VERSION ""

NS_ :

BS_:

BU_: XXX LKAS ADRV SCC

CM_ "Kia EV4 CAN-FD DBC - Based on current confirmed & partially confirmed signals";
CM_ "Base: Hyundai/Kia CAN-FD platform (E-GMP / EV4)";
CM_ "Vehicle: Kia EV4 2024+";
CM_ "Status: WIP - Steering FD frame (0x395) updated based on drive4 steering-only logs";

BO_ 256 VEHICLE_STATE: 24 XXX
 SG_ COUNTER                     : 0|8@1+  (1,0) [0|255] "" XXX
 SG_ CHECKSUM                    : 8|8@1+  (1,0) [0|255] "" XXX
 SG_ COUNTER2                    : 16|8@1+ (1,0) [0|255] "" XXX
 SG_ GEAR_SHIFTER                : 32|4@1+ (1,0) [0|15] "" XXX
 SG_ DOOR_FL                     : 72|1@1+ (1,0) [0|1] "" XXX
 SG_ DOOR_FR                     : 73|1@1+ (1,0) [0|1] "" XXX
 SG_ DOOR_RL                     : 74|1@1+ (1,0) [0|1] "" XXX
 SG_ DOOR_RR                     : 75|1@1+ (1,0) [0|1] "" XXX
 SG_ SEATBELT_DRIVER_LATCHED     : 76|1@1+ (1,0) [0|1] "" XXX
 SG_ PARKING_BRAKE               : 119|1@1+ (1,0) [0|1] "" XXX

BO_ 272 POWERTRAIN: 32 XXX
 SG_ COUNTER                     : 0|8@1+  (1,0) [0|255] "" XXX
 SG_ CHECKSUM                    : 8|8@1+  (1,0) [0|255] "" XXX
 SG_ COUNTER2                    : 16|8@1+ (1,0) [0|255] "" XXX
 SG_ LEFT_BLINKER                : 168|1@1+ (1,0) [0|1] "" XXX
 SG_ RIGHT_BLINKER               : 169|1@1+ (1,0) [0|1] "" XXX
 SG_ REGEN_LEVEL                 : 176|4@1+ (1,0) [0|3] "" XXX

BO_ 357 BRAKE_ACCEL: 16 XXX
 SG_ COUNTER                     : 0|8@1+  (1,0) [0|255] "" XXX
 SG_ CHECKSUM                    : 8|8@1+  (1,0) [0|255] "" XXX
 SG_ COUNTER2                    : 16|8@1+ (1,0) [0|255] "" XXX
 SG_ BRAKE_PRESSURE              : 24|8@1+ (1,0) [0|255] "" XXX
 SG_ GAS_PEDAL                   : 40|8@1+ (1,0) [0|255] "" XXX

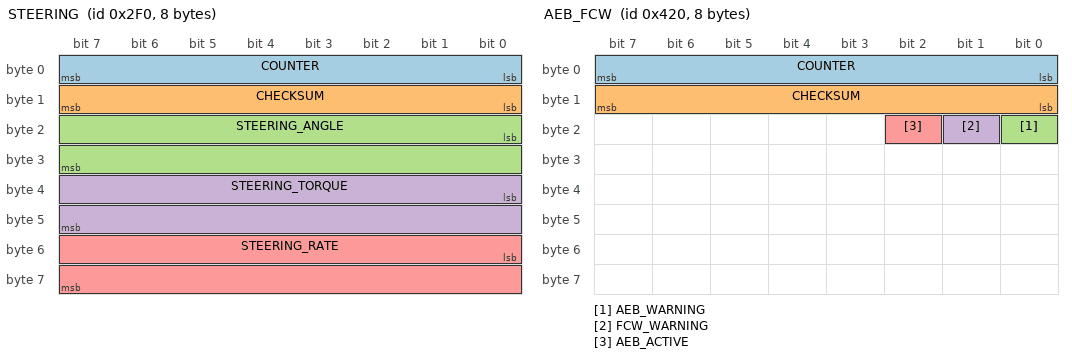
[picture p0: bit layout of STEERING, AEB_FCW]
BO_ 752 STEERING: 8 XXX
 SG_ COUNTER                     : 0|8@1+   (1,0) [0|255] "" XXX
 SG_ CHECKSUM                    : 8|8@1+   (1,0) [0|255] "" XXX
 SG_ STEERING_ANGLE              : 16|16@1- (0.1,0) [-450|450] "deg" XXX
 SG_ STEERING_TORQUE             : 32|16@1- (0.1,0) [-50|50] "Nm" XXX
 SG_ STEERING_RATE               : 48|16@1- (0.1,0) [-500|500] "deg/s" XXX

BO_ 864 WHEEL_SPEEDS_FL_RL: 32 XXX
 SG_ COUNTER                     : 0|8@1+  (1,0) [0|255] "" XXX
 SG_ CHECKSUM                    : 8|8@1+  (1,0) [0|255] "" XXX
 SG_ COUNTER2                    : 16|8@1+ (1,0) [0|255] "" XXX
 SG_ WHEEL_SPEED_FL              : 0|16@1+ (0.03125,0) [0|250] "kph" XXX
 SG_ WHEEL_SPEED_RL              : 16|16@1+ (0.03125,0) [0|250] "kph" XXX

BO_ 865 WHEEL_SPEEDS_FR_RR: 32 XXX
 SG_ COUNTER                     : 0|8@1+  (1,0) [0|255] "" XXX
 SG_ CHECKSUM                    : 8|8@1+  (1,0) [0|255] "" XXX
 SG_ COUNTER2                    : 16|8@1+ (1,0) [0|255] "" XXX
 SG_ WHEEL_SPEED_FR              : 0|16@1+ (0.03125,0) [0|250] "kph" XXX
 SG_ WHEEL_SPEED_RR              : 16|16@1+ (0.03125,0) [0|250] "kph" XXX

BO_ 896 TCS_ESC: 24 XXX
 SG_ COUNTER                     : 0|8@1+  (1,0) [0|255] "" XXX
 SG_ CHECKSUM                    : 8|8@1+  (1,0) [0|255] "" XXX
 SG_ COUNTER2                    : 16|8@1+ (1,0) [0|255] "" XXX
 SG_ ESP_DISABLED                : 24|1@1+ (1,0) [0|1] "" XXX
 SG_ ESP_ACTIVE                  : 25|1@1+ (1,0) [0|1] "" XXX
 SG_ TRACTION_CONTROL            : 26|1@1+ (1,0) [0|1] "" XXX
 SG_ ABS_ACTIVE                  : 27|1@1+ (1,0) [0|1] "" XXX

BO_ 917 STEERING_FD: 32 XXX
 SG_ STEER_FD_RAW_BYTE0         : 0|8@1+  (1,0) [0|255] "" XXX
 SG_ STEER_FD_RAW_BYTE1         : 8|8@1+  (1,0) [0|255] "" XXX
 SG_ STEER_FD_RAW_BYTE2         : 16|8@1+ (1,0) [0|255] "" XXX
 SG_ STEER_FD_STATUS_BYTE9      : 72|8@1+ (1,0) [0|255] "" XXX
 SG_ STEER_FD_STATUS_BYTE10     : 80|8@1+ (1,0) [0|255] "" XXX
 SG_ STEER_FD_STATUS_BYTE11     : 88|8@1+ (1,0) [0|255] "" XXX

BO_ 933 SCC_CONTROL: 24 XXX
 SG_ COUNTER                     : 0|8@1+  (1,0) [0|255] "" XXX
 SG_ CHECKSUM                    : 8|8@1+  (1,0) [0|255] "" XXX
 SG_ COUNTER2                    : 16|8@1+ (1,0) [0|255] "" XXX
 SG_ CRUISE_ACTIVE               : 24|1@1+ (1,0) [0|1] "" XXX
 SG_ CRUISE_STANDSTILL           : 25|1@1+ (1,0) [0|1] "" XXX
 SG_ CRUISE_AVAILABLE            : 26|1@1+ (1,0) [0|1] "" XXX
 SG_ SET_SPEED                   : 32|8@1+ (1,0) [0|255] "kph" XXX
 SG_ LEAD_DISTANCE               : 40|8@1+ (1,0) [0|255] "m" XXX
 SG_ LEAD_SPEED                  : 48|16@1- (0.1,0) [-200|200] "kph" XXX

BO_ 934 LKAS_1: 24 XXX
 SG_ COUNTER                     : 0|8@1+  (1,0) [0|255] "" XXX
 SG_ CHECKSUM                    : 8|8@1+  (1,0) [0|255] "" XXX
 SG_ COUNTER2                    : 16|8@1+ (1,0) [0|255] "" XXX
 SG_ LFA_ACTIVE                  : 24|1@1+ (1,0) [0|1] "" XXX
 SG_ LFA_AVAILABLE               : 25|1@1+ (1,0) [0|1] "" XXX
 SG_ LANE_DISTANCE_LEFT          : 32|8@1+ (0.01,0) [0|2.55] "m" XXX
 SG_ LANE_DISTANCE_RIGHT         : 40|8@1+ (0.01,0) [0|2.55] "m" XXX

BO_ 935 LKAS_2: 24 XXX
 SG_ COUNTER                     : 0|8@1+  (1,0) [0|255] "" XXX
 SG_ CHECKSUM                    : 8|8@1+  (1,0) [0|255] "" XXX
 SG_ COUNTER2                    : 16|8@1+ (1,0) [0|255] "" XXX
 SG_ LANE_DETECTED               : 24|1@1+ (1,0) [0|1] "" XXX
 SG_ LEFT_LANE_DETECTED          : 25|1@1+ (1,0) [0|1] "" XXX
 SG_ RIGHT_LANE_DETECTED         : 26|1@1+ (1,0) [0|1] "" XXX

BO_ 976 ADAS_1: 32 XXX
 SG_ COUNTER                     : 0|8@1+  (1,0) [0|255] "" XXX
 SG_ CHECKSUM                    : 8|8@1+  (1,0) [0|255] "" XXX
 SG_ COUNTER2                    : 16|8@1+ (1,0) [0|255] "" XXX
 SG_ ADAS_ENABLED                : 24|1@1+ (1,0) [0|1] "" XXX

BO_ 977 ADAS_2: 32 XXX
 SG_ COUNTER                     : 0|8@1+  (1,0) [0|255] "" XXX
 SG_ CHECKSUM                    : 8|8@1+  (1,0) [0|255] "" XXX
 SG_ COUNTER2                    : 16|8@1+ (1,0) [0|255] "" XXX

BO_ 1056 AEB_FCW: 8 XXX
 SG_ COUNTER                     : 0|8@1+  (1,0) [0|255] "" XXX
 SG_ CHECKSUM                    : 8|8@1+  (1,0) [0|255] "" XXX
 SG_ AEB_WARNING                 : 16|1@1+ (1,0) [0|1] "" XXX
 SG_ FCW_WARNING                 : 17|1@1+ (1,0) [0|1] "" XXX
 SG_ AEB_ACTIVE                  : 18|1@1+ (1,0) [0|1] "" XXX

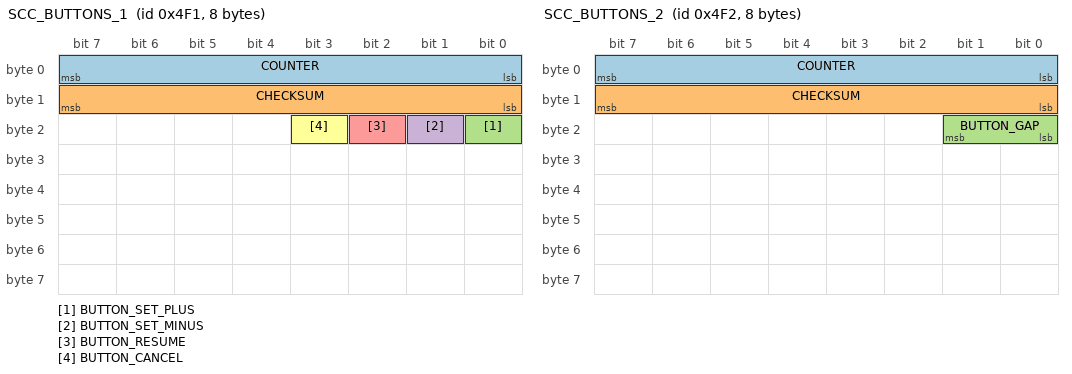
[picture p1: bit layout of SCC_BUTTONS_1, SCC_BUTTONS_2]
BO_ 1265 SCC_BUTTONS_1: 8 XXX
 SG_ COUNTER                     : 0|8@1+  (1,0) [0|255] "" XXX
 SG_ CHECKSUM                    : 8|8@1+  (1,0) [0|255] "" XXX
 SG_ BUTTON_SET_PLUS             : 16|1@1+ (1,0) [0|1] "" XXX
 SG_ BUTTON_SET_MINUS            : 17|1@1+ (1,0) [0|1] "" XXX
 SG_ BUTTON_RESUME               : 18|1@1+ (1,0) [0|1] "" XXX
 SG_ BUTTON_CANCEL               : 19|1@1+ (1,0) [0|1] "" XXX

BO_ 1266 SCC_BUTTONS_2: 8 XXX
 SG_ COUNTER                     : 0|8@1+  (1,0) [0|255] "" XXX
 SG_ CHECKSUM                    : 8|8@1+  (1,0) [0|255] "" XXX
 SG_ BUTTON_GAP                  : 16|2@1+ (1,0) [0|3] "" XXX

CM_ BO_ 256 "Vehicle state including gear, doors, seatbelt - Confirmed: Gear P/R/N/D";
CM_ BO_ 272 "Powertrain state including turn signals - Status: Turn signals unconfirmed";
CM_ BO_ 357 "Brake and accelerator pedal positions - Status: Gas pedal unconfirmed";
CM_ BO_ 752 "Steering wheel angle and torque (classic CAN) - PARTIAL: Needs validation vs CAN-FD";
CM_ BO_ 864 "Wheel speeds front left and rear left - Confirmed (from base platform)";
CM_ BO_ 865 "Wheel speeds front right and rear right - Confirmed (from base platform)";
CM_ BO_ 896 "TCS and ESC status - Confirmed (from base platform)";
CM_ BO_ 917 "EV4 Steering CAN-FD frame - drive4 정지+핸들락 테스트에서 bytes0-2가 조향에 따라 가장 크게 변화";
CM_ BO_ 933 "Smart Cruise Control status - Confirmed";
CM_ BO_ 934 "Lane Following Assist status 1 - Confirmed";
CM_ BO_ 935 "Lane Following Assist status 2 - Confirmed";
CM_ BO_ 976 "ADAS system 1 - Confirmed";
CM_ BO_ 977 "ADAS system 2 - Confirmed";
CM_ BO_ 1056 "AEB and FCW warnings - Confirmed";
CM_ BO_ 1265 "SCC buttons 1 - Status: Unconfirmed";
CM_ BO_ 1266 "SCC buttons 2 - Status: Unconfirmed";

CM_ SG_ 256 GEAR_SHIFTER              "Gear shifter position - CONFIRMED: 0=N, 1=R, 3=D, 5=P";
CM_ SG_ 752 STEERING_ANGLE            "Steering wheel angle - PARTIAL: classic CAN, needs CAN-FD cross-check";
CM_ SG_ 752 STEERING_TORQUE           "Driver steering torque - PARTIAL: Needs scale validation";
CM_ SG_ 272 LEFT_BLINKER              "Left turn signal - UNCONFIRMED: Needs testing";
CM_ SG_ 272 RIGHT_BLINKER             "Right turn signal - UNCONFIRMED: Needs testing";
CM_ SG_ 357 GAS_PEDAL                 "Accelerator pedal position - UNCONFIRMED: Needs testing";
CM_ SG_ 256 DOOR_FL                   "Front left door - UNCONFIRMED: Needs testing";
CM_ SG_ 256 DOOR_FR                   "Front right door - UNCONFIRMED: Needs testing";
CM_ SG_ 256 DOOR_RL                   "Rear left door - UNCONFIRMED: Needs testing";
CM_ SG_ 256 DOOR_RR                   "Rear right door - UNCONFIRMED: Needs testing";
CM_ SG_ 256 SEATBELT_DRIVER_LATCHED   "Driver seatbelt latched - UNCONFIRMED: Needs testing";
CM_ SG_ 256 PARKING_BRAKE             "Electronic parking brake - UNCONFIRMED: Needs testing";

VAL_ 256 GEAR_SHIFTER           0 "neutral" 1 "reverse" 3 "drive" 5 "park" ;
VAL_ 272 LEFT_BLINKER           0 "off" 1 "on" ;
VAL_ 272 RIGHT_BLINKER          0 "off" 1 "on" ;
VAL_ 256 DOOR_FL                0 "closed" 1 "open" ;
VAL_ 256 DOOR_FR                0 "closed" 1 "open" ;
VAL_ 256 DOOR_RL                0 "closed" 1 "open" ;
VAL_ 256 DOOR_RR                0 "closed" 1 "open" ;
VAL_ 256 SEATBELT_DRIVER_LATCHED 0 "unlatched" 1 "latched" ;
VAL_ 256 PARKING_BRAKE          0 "released" 1 "engaged" ;
VAL_ 896 ESP_DISABLED           0 "enabled" 1 "disabled" ;
VAL_ 896 ESP_ACTIVE             0 "inactive" 1 "active" ;
VAL_ 933 CRUISE_ACTIVE          0 "inactive" 1 "active" ;
VAL_ 933 CRUISE_STANDSTILL      0 "moving" 1 "standstill" ;
VAL_ 933 CRUISE_AVAILABLE       0 "unavailable" 1 "available" ;
VAL_ 934 LFA_ACTIVE             0 "inactive" 1 "active" ;
VAL_ 934 LFA_AVAILABLE          0 "unavailable" 1 "available" ;
VAL_ 1056 AEB_WARNING           0 "off" 1 "warning" ;
VAL_ 1056 FCW_WARNING           0 "off" 1 "warning" ;
VAL_ 1056 AEB_ACTIVE            0 "inactive" 1 "active" ;
